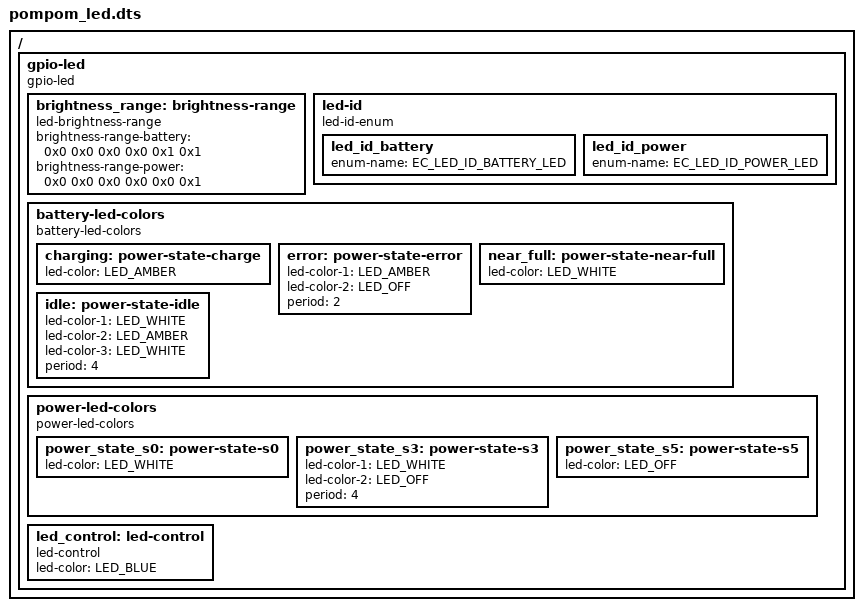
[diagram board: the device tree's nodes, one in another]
/ {
	gpio-led {
		compatible = "gpio-led";

		brightness_range: brightness-range {
			compatible = "led-brightness-range";

			brightness-range-battery = < 0x0 /* Red */
						     0x0 /* Green */
						     0x0 /* Blue */
						     0x0 /* Yellow */
						     0x1 /* White */
						     0x1 /* Amber */
						     >;

			brightness-range-power = < 0x0 /* Red */
						   0x0 /* Green */
						   0x0 /* Blue */
						   0x0 /* Yellow */
						   0x0 /* White */
						   0x1 /* Amber */
						   >;
		};

		led-id {
			compatible = "led-id-enum";

			led_id_battery {
				enum-name = "EC_LED_ID_BATTERY_LED";
			};

			led_id_power {
				enum-name = "EC_LED_ID_POWER_LED";
			};
		};

		battery-led-colors {
			compatible = "battery-led-colors";

			charging: power-state-charge {
				led-color = "LED_AMBER";
			};

			error: power-state-error {
				led-color-1 = "LED_AMBER";
				led-color-2 = "LED_OFF";
				period = <2>; // Amber 1 sec, off 1 sec
			};

			near_full: power-state-near-full {
				led-color = "LED_WHITE";
			};

			idle: power-state-idle {
				led-color-1 = "LED_WHITE";
				led-color-2 = "LED_AMBER";
				led-color-3 = "LED_WHITE";
				period = <4>; // White 2 sec, Amber sec
			};
		};

		power-led-colors {
			compatible = "power-led-colors";

			power_state_s0: power-state-s0 {
				led-color = "LED_WHITE";
			};

			power_state_s3: power-state-s3 {
				led-color-1 = "LED_WHITE";
				led-color-2 = "LED_OFF";
				period = <4>; // White 1 sec, off 3 sec
			};

			power_state_s5: power-state-s5 {
				led-color = "LED_OFF";
			};
		};

		led_control: led-control {
			compatible = "led-control";

			led-color = "LED_BLUE";
		};
	};
};
